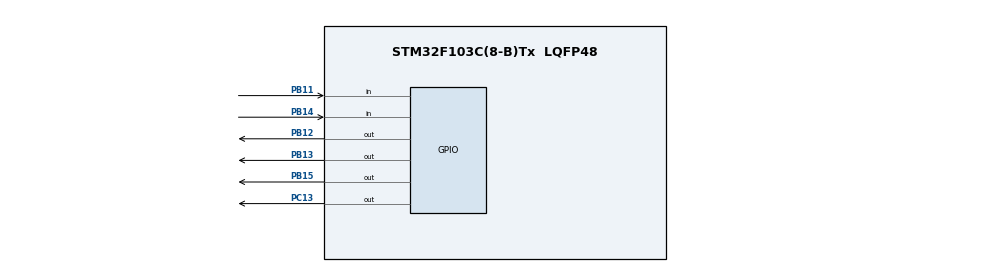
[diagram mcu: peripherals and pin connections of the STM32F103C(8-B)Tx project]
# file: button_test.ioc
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Mcu.Family=STM32F1
Mcu.Name=STM32F103C(8-B)Tx
Mcu.Package=LQFP48
NVIC.PriorityGroup=NVIC_PRIORITYGROUP_4
PB11.Signal=GPIO_Input
PB12.Signal=GPIO_Output
PB13.Signal=GPIO_Output
PB14.Signal=GPIO_Input
PB15.Signal=GPIO_Output
PC13-TAMPER-RTC.Signal=GPIO_Output
ProjectManager.HeapSize=0x200
ProjectManager.StackSize=0x400
ProjectManager.TargetToolchain=Makefile
RCC.APB1Freq_Value=8000000
RCC.APB2Freq_Value=8000000
VP_SYS_VS_ND.Mode=No_Debug
board=custom

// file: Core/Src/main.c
/* USER CODE BEGIN Header */
/**
  ******************************************************************************
  * @file           : main.c
  * @brief          : Main program body
  ******************************************************************************
  * @attention
  *
  * <h2><center>&copy; Copyright (c) 2021 STMicroelectronics.
  * All rights reserved.</center></h2>
  *
  * This software component is licensed by ST under BSD 3-Clause license,
  * the "License"; You may not use this file except in compliance with the
  * License. You may obtain a copy of the License at:
  *                        opensource.org/licenses/BSD-3-Clause
  *
  ******************************************************************************
  */
/* USER CODE END Header */
#include "main.h"

void SystemClock_Config(void);
static void MX_GPIO_Init(void);

int main(void)
{
  /* USER CODE BEGIN 1 */
	uint8_t button_status = 0;
	uint8_t old_button_status = 0;
	uint8_t counter = 0;

  /* USER CODE END 1 */

  /* MCU Configuration--------------------------------------------------------*/

  /* Reset of all peripherals, Initializes the Flash interface and the Systick. */
  HAL_Init();

  /* Configure the system clock */
  SystemClock_Config();

  /* Initialize all configured peripherals */
  MX_GPIO_Init();

  /* Infinite loop */
  while (1)
  {
	button_status = HAL_GPIO_ReadPin(GPIOB, GPIO_PIN_11);
	if(button_status != old_button_status) {
		if(button_status == 1) {
			counter++;
			if(counter == 16)
				counter = 0;
		}
		if((counter & 1) == 1) {
			HAL_GPIO_WritePin(GPIOB, GPIO_PIN_12, 1);
		}
		else {
			HAL_GPIO_WritePin(GPIOB, GPIO_PIN_12, 0);
		}
		if((counter & 2) == 2) {
			HAL_GPIO_WritePin(GPIOB, GPIO_PIN_13, 1);
		}
		else {
			HAL_GPIO_WritePin(GPIOB, GPIO_PIN_13, 0);
		}
		if((counter & 4) == 4) {
			HAL_GPIO_WritePin(GPIOB, GPIO_PIN_14, 1);
		}
		else {
			HAL_GPIO_WritePin(GPIOB, GPIO_PIN_14, 0);
		}
    if((counter & 8) == 8) {
			HAL_GPIO_WritePin(GPIOB, GPIO_PIN_15, 1);
		}
		else {
			HAL_GPIO_WritePin(GPIOB, GPIO_PIN_15, 0);
		}
		old_button_status = button_status;
	}
	HAL_Delay(100);
  }
}

void SystemClock_Config(void)
{
  RCC_OscInitTypeDef RCC_OscInitStruct = {0};
  RCC_ClkInitTypeDef RCC_ClkInitStruct = {0};

  /** Initializes the RCC Oscillators according to the specified parameters
  * in the RCC_OscInitTypeDef structure.
  */
  RCC_OscInitStruct.OscillatorType = RCC_OSCILLATORTYPE_HSI;
  RCC_OscInitStruct.HSIState = RCC_HSI_ON;
  RCC_OscInitStruct.HSICalibrationValue = RCC_HSICALIBRATION_DEFAULT;
  RCC_OscInitStruct.PLL.PLLState = RCC_PLL_NONE;
  if (HAL_RCC_OscConfig(&RCC_OscInitStruct) != HAL_OK)
  {
    Error_Handler();
  }
  /** Initializes the CPU, AHB and APB buses clocks
  */
  RCC_ClkInitStruct.ClockType = RCC_CLOCKTYPE_HCLK|RCC_CLOCKTYPE_SYSCLK
                              |RCC_CLOCKTYPE_PCLK1|RCC_CLOCKTYPE_PCLK2;
  RCC_ClkInitStruct.SYSCLKSource = RCC_SYSCLKSOURCE_HSI;
  RCC_ClkInitStruct.AHBCLKDivider = RCC_SYSCLK_DIV1;
  RCC_ClkInitStruct.APB1CLKDivider = RCC_HCLK_DIV1;
  RCC_ClkInitStruct.APB2CLKDivider = RCC_HCLK_DIV1;

  if (HAL_RCC_ClockConfig(&RCC_ClkInitStruct, FLASH_LATENCY_0) != HAL_OK)
  {
    Error_Handler();
  }
}

static void MX_GPIO_Init(void)
{
  GPIO_InitTypeDef GPIO_InitStruct = {0};

  /* GPIO Ports Clock Enable */
  __HAL_RCC_GPIOC_CLK_ENABLE();
  __HAL_RCC_GPIOB_CLK_ENABLE();

  /*Configure GPIO pin Output Level */
  HAL_GPIO_WritePin(GPIOC, GPIO_PIN_13, GPIO_PIN_RESET);

  /*Configure GPIO pin Output Level */
  HAL_GPIO_WritePin(GPIOB, GPIO_PIN_12|GPIO_PIN_13|GPIO_PIN_15, GPIO_PIN_RESET);

  /*Configure GPIO pin : PC13 */
  GPIO_InitStruct.Pin = GPIO_PIN_13;
  GPIO_InitStruct.Mode = GPIO_MODE_OUTPUT_PP;
  GPIO_InitStruct.Pull = GPIO_NOPULL;
  GPIO_InitStruct.Speed = GPIO_SPEED_FREQ_LOW;
  HAL_GPIO_Init(GPIOC, &GPIO_InitStruct);

  /*Configure GPIO pins : PB11 */
  GPIO_InitStruct.Pin = GPIO_PIN_11;
  GPIO_InitStruct.Mode = GPIO_MODE_INPUT;
  GPIO_InitStruct.Pull = GPIO_NOPULL;
  HAL_GPIO_Init(GPIOB, &GPIO_InitStruct);

  /*Configure GPIO pins : PB12 PB13 PB14 PB15 */
  GPIO_InitStruct.Pin = GPIO_PIN_12|GPIO_PIN_13|GPIO_PIN_14|GPIO_PIN_15;
  GPIO_InitStruct.Mode = GPIO_MODE_OUTPUT_PP;
  GPIO_InitStruct.Pull = GPIO_NOPULL;
  GPIO_InitStruct.Speed = GPIO_SPEED_FREQ_LOW;
  HAL_GPIO_Init(GPIOB, &GPIO_InitStruct);

}

void Error_Handler(void)
{
  __disable_irq();
  while (1)
  {
  }
}

/************************ (C) COPYRIGHT STMicroelectronics *****END OF FILE****/
